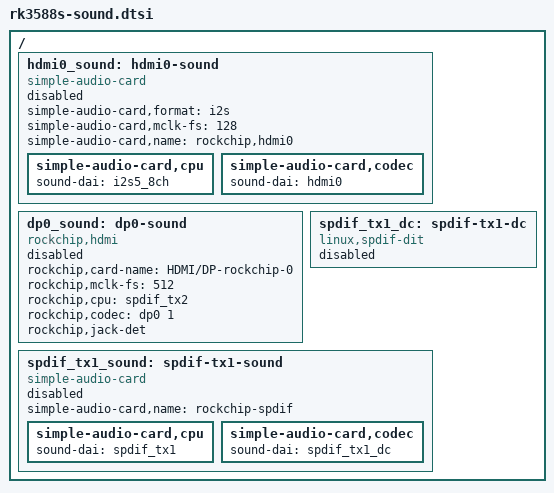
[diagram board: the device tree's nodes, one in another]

/ {
  hdmi0_sound: hdmi0-sound {
    status = "disabled";
    compatible = "simple-audio-card";
    simple-audio-card,format = "i2s";
    simple-audio-card,mclk-fs = <128>;
    simple-audio-card,name = "rockchip,hdmi0";

    simple-audio-card,cpu {
      sound-dai = <&i2s5_8ch>;
    };
    simple-audio-card,codec {
      sound-dai = <&hdmi0>;
    };
  };

  dp0_sound: dp0-sound {
      status = "disabled";
      compatible = "rockchip,hdmi";
      rockchip,card-name = "HDMI/DP-rockchip-0";
      rockchip,mclk-fs = <512>;
      rockchip,cpu = <&spdif_tx2>;
      rockchip,codec = <&dp0 1>;
      rockchip,jack-det;
  };

  spdif_tx1_dc: spdif-tx1-dc {
    status = "disabled";
    compatible = "linux,spdif-dit";
    #sound-dai-cells = <0>;
  };

  spdif_tx1_sound: spdif-tx1-sound {
    status = "disabled";
    compatible = "simple-audio-card";
    simple-audio-card,name = "rockchip-spdif";
    simple-audio-card,cpu {
      sound-dai = <&spdif_tx1>;
    };
    simple-audio-card,codec {
      sound-dai = <&spdif_tx1_dc>;
    };
  };
};
